AUTOSAR XML (schema 4-0-3)
package /AUTOSAR_NvM/SwComponentTypes
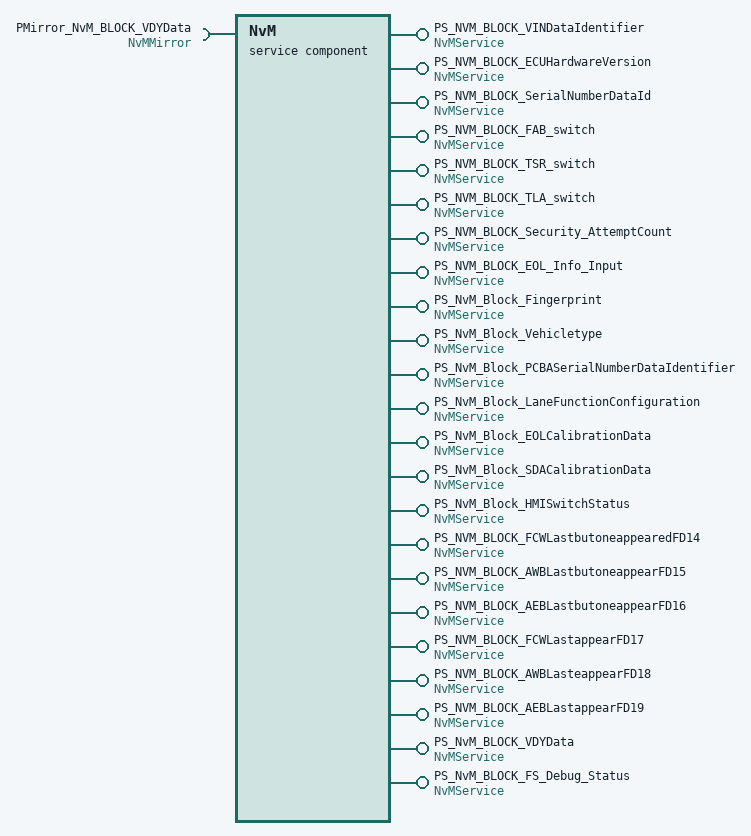
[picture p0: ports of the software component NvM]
  service sw component type NvM
    23 x provide port, all with provided-interface=NvMService:
      PS_NVM_BLOCK_VINDataIdentifier
      PS_NVM_BLOCK_ECUHardwareVersion
      PS_NVM_BLOCK_SerialNumberDataId
      PS_NVM_BLOCK_FAB_switch
      PS_NVM_BLOCK_TSR_switch
      PS_NVM_BLOCK_TLA_switch
      PS_NVM_BLOCK_Security_AttemptCount
      PS_NVM_BLOCK_EOL_Info_Input
      PS_NvM_Block_Fingerprint
      PS_NvM_Block_Vehicletype
      PS_NvM_Block_PCBASerialNumberDataIdentifier
      PS_NvM_Block_LaneFunctionConfiguration
      PS_NvM_Block_EOLCalibrationData
      PS_NvM_Block_SDACalibrationData
      PS_NvM_Block_HMISwitchStatus
      PS_NVM_BLOCK_FCWLastbutoneappearedFD14
      PS_NVM_BLOCK_AWBLastbutoneappearFD15
      PS_NVM_BLOCK_AEBLastbutoneappearFD16
      PS_NVM_BLOCK_FCWLastappearFD17
      PS_NVM_BLOCK_AWBLasteappearFD18
      PS_NVM_BLOCK_AEBLastappearFD19
      PS_NvM_BLOCK_VDYData
      PS_NvM_BLOCK_FS_Debug_Status
    require port PMirror_NvM_BLOCK_VDYData: required-interface=NvMMirror
    behavior NvMIntBeh: handle-termination-and-restart=NO-SUPPORT
      207 x operation invoked event:
        EV_GetErrorStatus_NVM_BLOCK_VINDataIdentifier: start-on-event=RE_GetErrorStatus, operation=PS_NVM_BLOCK_VINDataIdentifier.GetErrorStatus
        EV_SetDataIndex_NVM_BLOCK_VINDataIdentifier: start-on-event=RE_SetDataIndex, operation=PS_NVM_BLOCK_VINDataIdentifier.SetDataIndex
        EV_GetDataIndex_NVM_BLOCK_VINDataIdentifier: start-on-event=RE_GetDataIndex, operation=PS_NVM_BLOCK_VINDataIdentifier.GetDataIndex
        EV_SetRamBlockStatus_NVM_BLOCK_VINDataIdentifier: start-on-event=RE_SetRamBlockStatus, operation=PS_NVM_BLOCK_VINDataIdentifier.SetRamBlockStatus
        EV_ReadBlock_NVM_BLOCK_VINDataIdentifier: start-on-event=RE_ReadBlock, operation=PS_NVM_BLOCK_VINDataIdentifier.ReadBlock
        EV_WriteBlock_NVM_BLOCK_VINDataIdentifier: start-on-event=RE_WriteBlock, operation=PS_NVM_BLOCK_VINDataIdentifier.WriteBlock
        EV_RestoreBlockDefaults_NVM_BLOCK_VINDataIdentifier: start-on-event=RE_RestoreBlockDefaults, operation=PS_NVM_BLOCK_VINDataIdentifier.RestoreBlockDefaults
        EV_EraseBlock_NVM_BLOCK_VINDataIdentifier: start-on-event=RE_EraseBlock, operation=PS_NVM_BLOCK_VINDataIdentifier.EraseBlock
        EV_InvalidateNvBlock_NVM_BLOCK_VINDataIdentifier: start-on-event=RE_InvalidateNvBlock, operation=PS_NVM_BLOCK_VINDataIdentifier.InvalidateNvBlock
        EV_GetErrorStatus_NVM_BLOCK_ECUHardwareVersion: start-on-event=RE_GetErrorStatus, operation=PS_NVM_BLOCK_ECUHardwareVersion.GetErrorStatus
        EV_SetDataIndex_NVM_BLOCK_ECUHardwareVersion: start-on-event=RE_SetDataIndex, operation=PS_NVM_BLOCK_ECUHardwareVersion.SetDataIndex
        EV_GetDataIndex_NVM_BLOCK_ECUHardwareVersion: start-on-event=RE_GetDataIndex, operation=PS_NVM_BLOCK_ECUHardwareVersion.GetDataIndex
        EV_SetRamBlockStatus_NVM_BLOCK_ECUHardwareVersion: start-on-event=RE_SetRamBlockStatus, operation=PS_NVM_BLOCK_ECUHardwareVersion.SetRamBlockStatus
        EV_ReadBlock_NVM_BLOCK_ECUHardwareVersion: start-on-event=RE_ReadBlock, operation=PS_NVM_BLOCK_ECUHardwareVersion.ReadBlock
        EV_WriteBlock_NVM_BLOCK_ECUHardwareVersion: start-on-event=RE_WriteBlock, operation=PS_NVM_BLOCK_ECUHardwareVersion.WriteBlock
        EV_RestoreBlockDefaults_NVM_BLOCK_ECUHardwareVersion: start-on-event=RE_RestoreBlockDefaults, operation=PS_NVM_BLOCK_ECUHardwareVersion.RestoreBlockDefaults
        EV_EraseBlock_NVM_BLOCK_ECUHardwareVersion: start-on-event=RE_EraseBlock, operation=PS_NVM_BLOCK_ECUHardwareVersion.EraseBlock
        EV_InvalidateNvBlock_NVM_BLOCK_ECUHardwareVersion: start-on-event=RE_InvalidateNvBlock, operation=PS_NVM_BLOCK_ECUHardwareVersion.InvalidateNvBlock
        EV_GetErrorStatus_NVM_BLOCK_SerialNumberDataId: start-on-event=RE_GetErrorStatus, operation=PS_NVM_BLOCK_SerialNumberDataId.GetErrorStatus
        EV_SetDataIndex_NVM_BLOCK_SerialNumberDataId: start-on-event=RE_SetDataIndex, operation=PS_NVM_BLOCK_SerialNumberDataId.SetDataIndex
        EV_GetDataIndex_NVM_BLOCK_SerialNumberDataId: start-on-event=RE_GetDataIndex, operation=PS_NVM_BLOCK_SerialNumberDataId.GetDataIndex
        EV_SetRamBlockStatus_NVM_BLOCK_SerialNumberDataId: start-on-event=RE_SetRamBlockStatus, operation=PS_NVM_BLOCK_SerialNumberDataId.SetRamBlockStatus
        EV_ReadBlock_NVM_BLOCK_SerialNumberDataId: start-on-event=RE_ReadBlock, operation=PS_NVM_BLOCK_SerialNumberDataId.ReadBlock
        EV_WriteBlock_NVM_BLOCK_SerialNumberDataId: start-on-event=RE_WriteBlock, operation=PS_NVM_BLOCK_SerialNumberDataId.WriteBlock
        EV_RestoreBlockDefaults_NVM_BLOCK_SerialNumberDataId: start-on-event=RE_RestoreBlockDefaults, operation=PS_NVM_BLOCK_SerialNumberDataId.RestoreBlockDefaults
        EV_EraseBlock_NVM_BLOCK_SerialNumberDataId: start-on-event=RE_EraseBlock, operation=PS_NVM_BLOCK_SerialNumberDataId.EraseBlock
        EV_InvalidateNvBlock_NVM_BLOCK_SerialNumberDataId: start-on-event=RE_InvalidateNvBlock, operation=PS_NVM_BLOCK_SerialNumberDataId.InvalidateNvBlock
        EV_GetErrorStatus_NVM_BLOCK_FAB_switch: start-on-event=RE_GetErrorStatus, operation=PS_NVM_BLOCK_FAB_switch.GetErrorStatus
        EV_SetDataIndex_NVM_BLOCK_FAB_switch: start-on-event=RE_SetDataIndex, operation=PS_NVM_BLOCK_FAB_switch.SetDataIndex
        EV_GetDataIndex_NVM_BLOCK_FAB_switch: start-on-event=RE_GetDataIndex, operation=PS_NVM_BLOCK_FAB_switch.GetDataIndex
        EV_SetRamBlockStatus_NVM_BLOCK_FAB_switch: start-on-event=RE_SetRamBlockStatus, operation=PS_NVM_BLOCK_FAB_switch.SetRamBlockStatus
        EV_ReadBlock_NVM_BLOCK_FAB_switch: start-on-event=RE_ReadBlock, operation=PS_NVM_BLOCK_FAB_switch.ReadBlock
        EV_WriteBlock_NVM_BLOCK_FAB_switch: start-on-event=RE_WriteBlock, operation=PS_NVM_BLOCK_FAB_switch.WriteBlock
        EV_RestoreBlockDefaults_NVM_BLOCK_FAB_switch: start-on-event=RE_RestoreBlockDefaults, operation=PS_NVM_BLOCK_FAB_switch.RestoreBlockDefaults
        EV_EraseBlock_NVM_BLOCK_FAB_switch: start-on-event=RE_EraseBlock, operation=PS_NVM_BLOCK_FAB_switch.EraseBlock
        EV_InvalidateNvBlock_NVM_BLOCK_FAB_switch: start-on-event=RE_InvalidateNvBlock, operation=PS_NVM_BLOCK_FAB_switch.InvalidateNvBlock
        EV_GetErrorStatus_NVM_BLOCK_TSR_switch: start-on-event=RE_GetErrorStatus, operation=PS_NVM_BLOCK_TSR_switch.GetErrorStatus
        EV_SetDataIndex_NVM_BLOCK_TSR_switch: start-on-event=RE_SetDataIndex, operation=PS_NVM_BLOCK_TSR_switch.SetDataIndex
        EV_GetDataIndex_NVM_BLOCK_TSR_switch: start-on-event=RE_GetDataIndex, operation=PS_NVM_BLOCK_TSR_switch.GetDataIndex
        EV_SetRamBlockStatus_NVM_BLOCK_TSR_switch: start-on-event=RE_SetRamBlockStatus, operation=PS_NVM_BLOCK_TSR_switch.SetRamBlockStatus
        EV_ReadBlock_NVM_BLOCK_TSR_switch: start-on-event=RE_ReadBlock, operation=PS_NVM_BLOCK_TSR_switch.ReadBlock
        EV_WriteBlock_NVM_BLOCK_TSR_switch: start-on-event=RE_WriteBlock, operation=PS_NVM_BLOCK_TSR_switch.WriteBlock
        EV_RestoreBlockDefaults_NVM_BLOCK_TSR_switch: start-on-event=RE_RestoreBlockDefaults, operation=PS_NVM_BLOCK_TSR_switch.RestoreBlockDefaults
        EV_EraseBlock_NVM_BLOCK_TSR_switch: start-on-event=RE_EraseBlock, operation=PS_NVM_BLOCK_TSR_switch.EraseBlock
        EV_InvalidateNvBlock_NVM_BLOCK_TSR_switch: start-on-event=RE_InvalidateNvBlock, operation=PS_NVM_BLOCK_TSR_switch.InvalidateNvBlock
        EV_GetErrorStatus_NVM_BLOCK_TLA_switch: start-on-event=RE_GetErrorStatus, operation=PS_NVM_BLOCK_TLA_switch.GetErrorStatus
        EV_SetDataIndex_NVM_BLOCK_TLA_switch: start-on-event=RE_SetDataIndex, operation=PS_NVM_BLOCK_TLA_switch.SetDataIndex
        EV_GetDataIndex_NVM_BLOCK_TLA_switch: start-on-event=RE_GetDataIndex, operation=PS_NVM_BLOCK_TLA_switch.GetDataIndex
        EV_SetRamBlockStatus_NVM_BLOCK_TLA_switch: start-on-event=RE_SetRamBlockStatus, operation=PS_NVM_BLOCK_TLA_switch.SetRamBlockStatus
        EV_ReadBlock_NVM_BLOCK_TLA_switch: start-on-event=RE_ReadBlock, operation=PS_NVM_BLOCK_TLA_switch.ReadBlock
        EV_WriteBlock_NVM_BLOCK_TLA_switch: start-on-event=RE_WriteBlock, operation=PS_NVM_BLOCK_TLA_switch.WriteBlock
        EV_RestoreBlockDefaults_NVM_BLOCK_TLA_switch: start-on-event=RE_RestoreBlockDefaults, operation=PS_NVM_BLOCK_TLA_switch.RestoreBlockDefaults
        EV_EraseBlock_NVM_BLOCK_TLA_switch: start-on-event=RE_EraseBlock, operation=PS_NVM_BLOCK_TLA_switch.EraseBlock
        EV_InvalidateNvBlock_NVM_BLOCK_TLA_switch: start-on-event=RE_InvalidateNvBlock, operation=PS_NVM_BLOCK_TLA_switch.InvalidateNvBlock
        EV_GetErrorStatus_NVM_BLOCK_Security_AttemptCount: start-on-event=RE_GetErrorStatus, operation=PS_NVM_BLOCK_Security_AttemptCount.GetErrorStatus
        EV_SetDataIndex_NVM_BLOCK_Security_AttemptCount: start-on-event=RE_SetDataIndex, operation=PS_NVM_BLOCK_Security_AttemptCount.SetDataIndex
        EV_GetDataIndex_NVM_BLOCK_Security_AttemptCount: start-on-event=RE_GetDataIndex, operation=PS_NVM_BLOCK_Security_AttemptCount.GetDataIndex
        EV_SetRamBlockStatus_NVM_BLOCK_Security_AttemptCount: start-on-event=RE_SetRamBlockStatus, operation=PS_NVM_BLOCK_Security_AttemptCount.SetRamBlockStatus
        EV_ReadBlock_NVM_BLOCK_Security_AttemptCount: start-on-event=RE_ReadBlock, operation=PS_NVM_BLOCK_Security_AttemptCount.ReadBlock
        EV_WriteBlock_NVM_BLOCK_Security_AttemptCount: start-on-event=RE_WriteBlock, operation=PS_NVM_BLOCK_Security_AttemptCount.WriteBlock
        EV_RestoreBlockDefaults_NVM_BLOCK_Security_AttemptCount: start-on-event=RE_RestoreBlockDefaults, operation=PS_NVM_BLOCK_Security_AttemptCount.RestoreBlockDefaults
        EV_EraseBlock_NVM_BLOCK_Security_AttemptCount: start-on-event=RE_EraseBlock, operation=PS_NVM_BLOCK_Security_AttemptCount.EraseBlock
        EV_InvalidateNvBlock_NVM_BLOCK_Security_AttemptCount: start-on-event=RE_InvalidateNvBlock, operation=PS_NVM_BLOCK_Security_AttemptCount.InvalidateNvBlock
        EV_GetErrorStatus_NVM_BLOCK_EOL_Info_Input: start-on-event=RE_GetErrorStatus, operation=PS_NVM_BLOCK_EOL_Info_Input.GetErrorStatus
        EV_SetDataIndex_NVM_BLOCK_EOL_Info_Input: start-on-event=RE_SetDataIndex, operation=PS_NVM_BLOCK_EOL_Info_Input.SetDataIndex
        EV_GetDataIndex_NVM_BLOCK_EOL_Info_Input: start-on-event=RE_GetDataIndex, operation=PS_NVM_BLOCK_EOL_Info_Input.GetDataIndex
        EV_SetRamBlockStatus_NVM_BLOCK_EOL_Info_Input: start-on-event=RE_SetRamBlockStatus, operation=PS_NVM_BLOCK_EOL_Info_Input.SetRamBlockStatus
        EV_ReadBlock_NVM_BLOCK_EOL_Info_Input: start-on-event=RE_ReadBlock, operation=PS_NVM_BLOCK_EOL_Info_Input.ReadBlock
        EV_WriteBlock_NVM_BLOCK_EOL_Info_Input: start-on-event=RE_WriteBlock, operation=PS_NVM_BLOCK_EOL_Info_Input.WriteBlock
        EV_RestoreBlockDefaults_NVM_BLOCK_EOL_Info_Input: start-on-event=RE_RestoreBlockDefaults, operation=PS_NVM_BLOCK_EOL_Info_Input.RestoreBlockDefaults
        EV_EraseBlock_NVM_BLOCK_EOL_Info_Input: start-on-event=RE_EraseBlock, operation=PS_NVM_BLOCK_EOL_Info_Input.EraseBlock
        EV_InvalidateNvBlock_NVM_BLOCK_EOL_Info_Input: start-on-event=RE_InvalidateNvBlock, operation=PS_NVM_BLOCK_EOL_Info_Input.InvalidateNvBlock
        EV_GetErrorStatus_NvM_Block_Fingerprint: start-on-event=RE_GetErrorStatus, operation=PS_NvM_Block_Fingerprint.GetErrorStatus
        EV_SetDataIndex_NvM_Block_Fingerprint: start-on-event=RE_SetDataIndex, operation=PS_NvM_Block_Fingerprint.SetDataIndex
        EV_GetDataIndex_NvM_Block_Fingerprint: start-on-event=RE_GetDataIndex, operation=PS_NvM_Block_Fingerprint.GetDataIndex
        EV_SetRamBlockStatus_NvM_Block_Fingerprint: start-on-event=RE_SetRamBlockStatus, operation=PS_NvM_Block_Fingerprint.SetRamBlockStatus
        EV_ReadBlock_NvM_Block_Fingerprint: start-on-event=RE_ReadBlock, operation=PS_NvM_Block_Fingerprint.ReadBlock
        EV_WriteBlock_NvM_Block_Fingerprint: start-on-event=RE_WriteBlock, operation=PS_NvM_Block_Fingerprint.WriteBlock
        EV_RestoreBlockDefaults_NvM_Block_Fingerprint: start-on-event=RE_RestoreBlockDefaults, operation=PS_NvM_Block_Fingerprint.RestoreBlockDefaults
        EV_EraseBlock_NvM_Block_Fingerprint: start-on-event=RE_EraseBlock, operation=PS_NvM_Block_Fingerprint.EraseBlock
        EV_InvalidateNvBlock_NvM_Block_Fingerprint: start-on-event=RE_InvalidateNvBlock, operation=PS_NvM_Block_Fingerprint.InvalidateNvBlock
        EV_GetErrorStatus_NvM_Block_Vehicletype: start-on-event=RE_GetErrorStatus, operation=PS_NvM_Block_Vehicletype.GetErrorStatus
        EV_SetDataIndex_NvM_Block_Vehicletype: start-on-event=RE_SetDataIndex, operation=PS_NvM_Block_Vehicletype.SetDataIndex
        EV_GetDataIndex_NvM_Block_Vehicletype: start-on-event=RE_GetDataIndex, operation=PS_NvM_Block_Vehicletype.GetDataIndex
        EV_SetRamBlockStatus_NvM_Block_Vehicletype: start-on-event=RE_SetRamBlockStatus, operation=PS_NvM_Block_Vehicletype.SetRamBlockStatus
        EV_ReadBlock_NvM_Block_Vehicletype: start-on-event=RE_ReadBlock, operation=PS_NvM_Block_Vehicletype.ReadBlock
        EV_WriteBlock_NvM_Block_Vehicletype: start-on-event=RE_WriteBlock, operation=PS_NvM_Block_Vehicletype.WriteBlock
        EV_RestoreBlockDefaults_NvM_Block_Vehicletype: start-on-event=RE_RestoreBlockDefaults, operation=PS_NvM_Block_Vehicletype.RestoreBlockDefaults
        EV_EraseBlock_NvM_Block_Vehicletype: start-on-event=RE_EraseBlock, operation=PS_NvM_Block_Vehicletype.EraseBlock
        EV_InvalidateNvBlock_NvM_Block_Vehicletype: start-on-event=RE_InvalidateNvBlock, operation=PS_NvM_Block_Vehicletype.InvalidateNvBlock
        EV_GetErrorStatus_NvM_Block_PCBASerialNumberDataIdentifier: start-on-event=RE_GetErrorStatus, operation=PS_NvM_Block_PCBASerialNumberDataIdentifier.GetErrorStatus
        EV_SetDataIndex_NvM_Block_PCBASerialNumberDataIdentifier: start-on-event=RE_SetDataIndex, operation=PS_NvM_Block_PCBASerialNumberDataIdentifier.SetDataIndex
        EV_GetDataIndex_NvM_Block_PCBASerialNumberDataIdentifier: start-on-event=RE_GetDataIndex, operation=PS_NvM_Block_PCBASerialNumberDataIdentifier.GetDataIndex
        EV_SetRamBlockStatus_NvM_Block_PCBASerialNumberDataIdentifier: start-on-event=RE_SetRamBlockStatus, operation=PS_NvM_Block_PCBASerialNumberDataIdentifier.SetRamBlockStatus
        EV_ReadBlock_NvM_Block_PCBASerialNumberDataIdentifier: start-on-event=RE_ReadBlock, operation=PS_NvM_Block_PCBASerialNumberDataIdentifier.ReadBlock
        EV_WriteBlock_NvM_Block_PCBASerialNumberDataIdentifier: start-on-event=RE_WriteBlock, operation=PS_NvM_Block_PCBASerialNumberDataIdentifier.WriteBlock
        EV_RestoreBlockDefaults_NvM_Block_PCBASerialNumberDataIdentifier: start-on-event=RE_RestoreBlockDefaults, operation=PS_NvM_Block_PCBASerialNumberDataIdentifier.RestoreBlockDefaults
        EV_EraseBlock_NvM_Block_PCBASerialNumberDataIdentifier: start-on-event=RE_EraseBlock, operation=PS_NvM_Block_PCBASerialNumberDataIdentifier.EraseBlock
        EV_InvalidateNvBlock_NvM_Block_PCBASerialNumberDataIdentifier: start-on-event=RE_InvalidateNvBlock, operation=PS_NvM_Block_PCBASerialNumberDataIdentifier.InvalidateNvBlock
        EV_GetErrorStatus_NvM_Block_LaneFunctionConfiguration: start-on-event=RE_GetErrorStatus, operation=PS_NvM_Block_LaneFunctionConfiguration.GetErrorStatus
        EV_SetDataIndex_NvM_Block_LaneFunctionConfiguration: start-on-event=RE_SetDataIndex, operation=PS_NvM_Block_LaneFunctionConfiguration.SetDataIndex
        EV_GetDataIndex_NvM_Block_LaneFunctionConfiguration: start-on-event=RE_GetDataIndex, operation=PS_NvM_Block_LaneFunctionConfiguration.GetDataIndex
        EV_SetRamBlockStatus_NvM_Block_LaneFunctionConfiguration: start-on-event=RE_SetRamBlockStatus, operation=PS_NvM_Block_LaneFunctionConfiguration.SetRamBlockStatus
        EV_ReadBlock_NvM_Block_LaneFunctionConfiguration: start-on-event=RE_ReadBlock, operation=PS_NvM_Block_LaneFunctionConfiguration.ReadBlock
        EV_WriteBlock_NvM_Block_LaneFunctionConfiguration: start-on-event=RE_WriteBlock, operation=PS_NvM_Block_LaneFunctionConfiguration.WriteBlock
        EV_RestoreBlockDefaults_NvM_Block_LaneFunctionConfiguration: start-on-event=RE_RestoreBlockDefaults, operation=PS_NvM_Block_LaneFunctionConfiguration.RestoreBlockDefaults
        EV_EraseBlock_NvM_Block_LaneFunctionConfiguration: start-on-event=RE_EraseBlock, operation=PS_NvM_Block_LaneFunctionConfiguration.EraseBlock
        EV_InvalidateNvBlock_NvM_Block_LaneFunctionConfiguration: start-on-event=RE_InvalidateNvBlock, operation=PS_NvM_Block_LaneFunctionConfiguration.InvalidateNvBlock
        EV_GetErrorStatus_NvM_Block_EOLCalibrationData: start-on-event=RE_GetErrorStatus, operation=PS_NvM_Block_EOLCalibrationData.GetErrorStatus
        EV_SetDataIndex_NvM_Block_EOLCalibrationData: start-on-event=RE_SetDataIndex, operation=PS_NvM_Block_EOLCalibrationData.SetDataIndex
        EV_GetDataIndex_NvM_Block_EOLCalibrationData: start-on-event=RE_GetDataIndex, operation=PS_NvM_Block_EOLCalibrationData.GetDataIndex
        EV_SetRamBlockStatus_NvM_Block_EOLCalibrationData: start-on-event=RE_SetRamBlockStatus, operation=PS_NvM_Block_EOLCalibrationData.SetRamBlockStatus
        EV_ReadBlock_NvM_Block_EOLCalibrationData: start-on-event=RE_ReadBlock, operation=PS_NvM_Block_EOLCalibrationData.ReadBlock
        EV_WriteBlock_NvM_Block_EOLCalibrationData: start-on-event=RE_WriteBlock, operation=PS_NvM_Block_EOLCalibrationData.WriteBlock
        EV_RestoreBlockDefaults_NvM_Block_EOLCalibrationData: start-on-event=RE_RestoreBlockDefaults, operation=PS_NvM_Block_EOLCalibrationData.RestoreBlockDefaults
        EV_EraseBlock_NvM_Block_EOLCalibrationData: start-on-event=RE_EraseBlock, operation=PS_NvM_Block_EOLCalibrationData.EraseBlock
        EV_InvalidateNvBlock_NvM_Block_EOLCalibrationData: start-on-event=RE_InvalidateNvBlock, operation=PS_NvM_Block_EOLCalibrationData.InvalidateNvBlock
        EV_GetErrorStatus_NvM_Block_SDACalibrationData: start-on-event=RE_GetErrorStatus, operation=PS_NvM_Block_SDACalibrationData.GetErrorStatus
        EV_SetDataIndex_NvM_Block_SDACalibrationData: start-on-event=RE_SetDataIndex, operation=PS_NvM_Block_SDACalibrationData.SetDataIndex
        EV_GetDataIndex_NvM_Block_SDACalibrationData: start-on-event=RE_GetDataIndex, operation=PS_NvM_Block_SDACalibrationData.GetDataIndex
        EV_SetRamBlockStatus_NvM_Block_SDACalibrationData: start-on-event=RE_SetRamBlockStatus, operation=PS_NvM_Block_SDACalibrationData.SetRamBlockStatus
        EV_ReadBlock_NvM_Block_SDACalibrationData: start-on-event=RE_ReadBlock, operation=PS_NvM_Block_SDACalibrationData.ReadBlock
        EV_WriteBlock_NvM_Block_SDACalibrationData: start-on-event=RE_WriteBlock, operation=PS_NvM_Block_SDACalibrationData.WriteBlock
        EV_RestoreBlockDefaults_NvM_Block_SDACalibrationData: start-on-event=RE_RestoreBlockDefaults, operation=PS_NvM_Block_SDACalibrationData.RestoreBlockDefaults
        EV_EraseBlock_NvM_Block_SDACalibrationData: start-on-event=RE_EraseBlock, operation=PS_NvM_Block_SDACalibrationData.EraseBlock
        EV_InvalidateNvBlock_NvM_Block_SDACalibrationData: start-on-event=RE_InvalidateNvBlock, operation=PS_NvM_Block_SDACalibrationData.InvalidateNvBlock
        EV_GetErrorStatus_NvM_Block_HMISwitchStatus: start-on-event=RE_GetErrorStatus, operation=PS_NvM_Block_HMISwitchStatus.GetErrorStatus
        EV_SetDataIndex_NvM_Block_HMISwitchStatus: start-on-event=RE_SetDataIndex, operation=PS_NvM_Block_HMISwitchStatus.SetDataIndex
        EV_GetDataIndex_NvM_Block_HMISwitchStatus: start-on-event=RE_GetDataIndex, operation=PS_NvM_Block_HMISwitchStatus.GetDataIndex
        EV_SetRamBlockStatus_NvM_Block_HMISwitchStatus: start-on-event=RE_SetRamBlockStatus, operation=PS_NvM_Block_HMISwitchStatus.SetRamBlockStatus
        EV_ReadBlock_NvM_Block_HMISwitchStatus: start-on-event=RE_ReadBlock, operation=PS_NvM_Block_HMISwitchStatus.ReadBlock
        EV_WriteBlock_NvM_Block_HMISwitchStatus: start-on-event=RE_WriteBlock, operation=PS_NvM_Block_HMISwitchStatus.WriteBlock
        EV_RestoreBlockDefaults_NvM_Block_HMISwitchStatus: start-on-event=RE_RestoreBlockDefaults, operation=PS_NvM_Block_HMISwitchStatus.RestoreBlockDefaults
        EV_EraseBlock_NvM_Block_HMISwitchStatus: start-on-event=RE_EraseBlock, operation=PS_NvM_Block_HMISwitchStatus.EraseBlock
        EV_InvalidateNvBlock_NvM_Block_HMISwitchStatus: start-on-event=RE_InvalidateNvBlock, operation=PS_NvM_Block_HMISwitchStatus.InvalidateNvBlock
        EV_GetErrorStatus_NVM_BLOCK_FCWLastbutoneappearedFD14: start-on-event=RE_GetErrorStatus, operation=PS_NVM_BLOCK_FCWLastbutoneappearedFD14.GetErrorStatus
        EV_SetDataIndex_NVM_BLOCK_FCWLastbutoneappearedFD14: start-on-event=RE_SetDataIndex, operation=PS_NVM_BLOCK_FCWLastbutoneappearedFD14.SetDataIndex
        EV_GetDataIndex_NVM_BLOCK_FCWLastbutoneappearedFD14: start-on-event=RE_GetDataIndex, operation=PS_NVM_BLOCK_FCWLastbutoneappearedFD14.GetDataIndex
        EV_SetRamBlockStatus_NVM_BLOCK_FCWLastbutoneappearedFD14: start-on-event=RE_SetRamBlockStatus, operation=PS_NVM_BLOCK_FCWLastbutoneappearedFD14.SetRamBlockStatus
        EV_ReadBlock_NVM_BLOCK_FCWLastbutoneappearedFD14: start-on-event=RE_ReadBlock, operation=PS_NVM_BLOCK_FCWLastbutoneappearedFD14.ReadBlock
        EV_WriteBlock_NVM_BLOCK_FCWLastbutoneappearedFD14: start-on-event=RE_WriteBlock, operation=PS_NVM_BLOCK_FCWLastbutoneappearedFD14.WriteBlock
        EV_RestoreBlockDefaults_NVM_BLOCK_FCWLastbutoneappearedFD14: start-on-event=RE_RestoreBlockDefaults, operation=PS_NVM_BLOCK_FCWLastbutoneappearedFD14.RestoreBlockDefaults
        EV_EraseBlock_NVM_BLOCK_FCWLastbutoneappearedFD14: start-on-event=RE_EraseBlock, operation=PS_NVM_BLOCK_FCWLastbutoneappearedFD14.EraseBlock
        EV_InvalidateNvBlock_NVM_BLOCK_FCWLastbutoneappearedFD14: start-on-event=RE_InvalidateNvBlock, operation=PS_NVM_BLOCK_FCWLastbutoneappearedFD14.InvalidateNvBlock
        EV_GetErrorStatus_NVM_BLOCK_AWBLastbutoneappearFD15: start-on-event=RE_GetErrorStatus, operation=PS_NVM_BLOCK_AWBLastbutoneappearFD15.GetErrorStatus
        EV_SetDataIndex_NVM_BLOCK_AWBLastbutoneappearFD15: start-on-event=RE_SetDataIndex, operation=PS_NVM_BLOCK_AWBLastbutoneappearFD15.SetDataIndex
        EV_GetDataIndex_NVM_BLOCK_AWBLastbutoneappearFD15: start-on-event=RE_GetDataIndex, operation=PS_NVM_BLOCK_AWBLastbutoneappearFD15.GetDataIndex
        EV_SetRamBlockStatus_NVM_BLOCK_AWBLastbutoneappearFD15: start-on-event=RE_SetRamBlockStatus, operation=PS_NVM_BLOCK_AWBLastbutoneappearFD15.SetRamBlockStatus
        EV_ReadBlock_NVM_BLOCK_AWBLastbutoneappearFD15: start-on-event=RE_ReadBlock, operation=PS_NVM_BLOCK_AWBLastbutoneappearFD15.ReadBlock
        EV_WriteBlock_NVM_BLOCK_AWBLastbutoneappearFD15: start-on-event=RE_WriteBlock, operation=PS_NVM_BLOCK_AWBLastbutoneappearFD15.WriteBlock
        EV_RestoreBlockDefaults_NVM_BLOCK_AWBLastbutoneappearFD15: start-on-event=RE_RestoreBlockDefaults, operation=PS_NVM_BLOCK_AWBLastbutoneappearFD15.RestoreBlockDefaults
        EV_EraseBlock_NVM_BLOCK_AWBLastbutoneappearFD15: start-on-event=RE_EraseBlock, operation=PS_NVM_BLOCK_AWBLastbutoneappearFD15.EraseBlock
        EV_InvalidateNvBlock_NVM_BLOCK_AWBLastbutoneappearFD15: start-on-event=RE_InvalidateNvBlock, operation=PS_NVM_BLOCK_AWBLastbutoneappearFD15.InvalidateNvBlock
        EV_GetErrorStatus_NVM_BLOCK_AEBLastbutoneappearFD16: start-on-event=RE_GetErrorStatus, operation=PS_NVM_BLOCK_AEBLastbutoneappearFD16.GetErrorStatus
        EV_SetDataIndex_NVM_BLOCK_AEBLastbutoneappearFD16: start-on-event=RE_SetDataIndex, operation=PS_NVM_BLOCK_AEBLastbutoneappearFD16.SetDataIndex
        EV_GetDataIndex_NVM_BLOCK_AEBLastbutoneappearFD16: start-on-event=RE_GetDataIndex, operation=PS_NVM_BLOCK_AEBLastbutoneappearFD16.GetDataIndex
        EV_SetRamBlockStatus_NVM_BLOCK_AEBLastbutoneappearFD16: start-on-event=RE_SetRamBlockStatus, operation=PS_NVM_BLOCK_AEBLastbutoneappearFD16.SetRamBlockStatus
        EV_ReadBlock_NVM_BLOCK_AEBLastbutoneappearFD16: start-on-event=RE_ReadBlock, operation=PS_NVM_BLOCK_AEBLastbutoneappearFD16.ReadBlock
        EV_WriteBlock_NVM_BLOCK_AEBLastbutoneappearFD16: start-on-event=RE_WriteBlock, operation=PS_NVM_BLOCK_AEBLastbutoneappearFD16.WriteBlock
        EV_RestoreBlockDefaults_NVM_BLOCK_AEBLastbutoneappearFD16: start-on-event=RE_RestoreBlockDefaults, operation=PS_NVM_BLOCK_AEBLastbutoneappearFD16.RestoreBlockDefaults
        EV_EraseBlock_NVM_BLOCK_AEBLastbutoneappearFD16: start-on-event=RE_EraseBlock, operation=PS_NVM_BLOCK_AEBLastbutoneappearFD16.EraseBlock
        EV_InvalidateNvBlock_NVM_BLOCK_AEBLastbutoneappearFD16: start-on-event=RE_InvalidateNvBlock, operation=PS_NVM_BLOCK_AEBLastbutoneappearFD16.InvalidateNvBlock
        EV_GetErrorStatus_NVM_BLOCK_FCWLastappearFD17: start-on-event=RE_GetErrorStatus, operation=PS_NVM_BLOCK_FCWLastappearFD17.GetErrorStatus
        EV_SetDataIndex_NVM_BLOCK_FCWLastappearFD17: start-on-event=RE_SetDataIndex, operation=PS_NVM_BLOCK_FCWLastappearFD17.SetDataIndex
        EV_GetDataIndex_NVM_BLOCK_FCWLastappearFD17: start-on-event=RE_GetDataIndex, operation=PS_NVM_BLOCK_FCWLastappearFD17.GetDataIndex
        EV_SetRamBlockStatus_NVM_BLOCK_FCWLastappearFD17: start-on-event=RE_SetRamBlockStatus, operation=PS_NVM_BLOCK_FCWLastappearFD17.SetRamBlockStatus
        EV_ReadBlock_NVM_BLOCK_FCWLastappearFD17: start-on-event=RE_ReadBlock, operation=PS_NVM_BLOCK_FCWLastappearFD17.ReadBlock
        EV_WriteBlock_NVM_BLOCK_FCWLastappearFD17: start-on-event=RE_WriteBlock, operation=PS_NVM_BLOCK_FCWLastappearFD17.WriteBlock
        EV_RestoreBlockDefaults_NVM_BLOCK_FCWLastappearFD17: start-on-event=RE_RestoreBlockDefaults, operation=PS_NVM_BLOCK_FCWLastappearFD17.RestoreBlockDefaults
        EV_EraseBlock_NVM_BLOCK_FCWLastappearFD17: start-on-event=RE_EraseBlock, operation=PS_NVM_BLOCK_FCWLastappearFD17.EraseBlock
        EV_InvalidateNvBlock_NVM_BLOCK_FCWLastappearFD17: start-on-event=RE_InvalidateNvBlock, operation=PS_NVM_BLOCK_FCWLastappearFD17.InvalidateNvBlock
        EV_GetErrorStatus_NVM_BLOCK_AWBLasteappearFD18: start-on-event=RE_GetErrorStatus, operation=PS_NVM_BLOCK_AWBLasteappearFD18.GetErrorStatus
        EV_SetDataIndex_NVM_BLOCK_AWBLasteappearFD18: start-on-event=RE_SetDataIndex, operation=PS_NVM_BLOCK_AWBLasteappearFD18.SetDataIndex
        EV_GetDataIndex_NVM_BLOCK_AWBLasteappearFD18: start-on-event=RE_GetDataIndex, operation=PS_NVM_BLOCK_AWBLasteappearFD18.GetDataIndex
        EV_SetRamBlockStatus_NVM_BLOCK_AWBLasteappearFD18: start-on-event=RE_SetRamBlockStatus, operation=PS_NVM_BLOCK_AWBLasteappearFD18.SetRamBlockStatus
        EV_ReadBlock_NVM_BLOCK_AWBLasteappearFD18: start-on-event=RE_ReadBlock, operation=PS_NVM_BLOCK_AWBLasteappearFD18.ReadBlock
        EV_WriteBlock_NVM_BLOCK_AWBLasteappearFD18: start-on-event=RE_WriteBlock, operation=PS_NVM_BLOCK_AWBLasteappearFD18.WriteBlock
        EV_RestoreBlockDefaults_NVM_BLOCK_AWBLasteappearFD18: start-on-event=RE_RestoreBlockDefaults, operation=PS_NVM_BLOCK_AWBLasteappearFD18.RestoreBlockDefaults
        EV_EraseBlock_NVM_BLOCK_AWBLasteappearFD18: start-on-event=RE_EraseBlock, operation=PS_NVM_BLOCK_AWBLasteappearFD18.EraseBlock
        EV_InvalidateNvBlock_NVM_BLOCK_AWBLasteappearFD18: start-on-event=RE_InvalidateNvBlock, operation=PS_NVM_BLOCK_AWBLasteappearFD18.InvalidateNvBlock
        EV_GetErrorStatus_NVM_BLOCK_AEBLastappearFD19: start-on-event=RE_GetErrorStatus, operation=PS_NVM_BLOCK_AEBLastappearFD19.GetErrorStatus
        EV_SetDataIndex_NVM_BLOCK_AEBLastappearFD19: start-on-event=RE_SetDataIndex, operation=PS_NVM_BLOCK_AEBLastappearFD19.SetDataIndex
        EV_GetDataIndex_NVM_BLOCK_AEBLastappearFD19: start-on-event=RE_GetDataIndex, operation=PS_NVM_BLOCK_AEBLastappearFD19.GetDataIndex
        EV_SetRamBlockStatus_NVM_BLOCK_AEBLastappearFD19: start-on-event=RE_SetRamBlockStatus, operation=PS_NVM_BLOCK_AEBLastappearFD19.SetRamBlockStatus
        EV_ReadBlock_NVM_BLOCK_AEBLastappearFD19: start-on-event=RE_ReadBlock, operation=PS_NVM_BLOCK_AEBLastappearFD19.ReadBlock
        EV_WriteBlock_NVM_BLOCK_AEBLastappearFD19: start-on-event=RE_WriteBlock, operation=PS_NVM_BLOCK_AEBLastappearFD19.WriteBlock
        EV_RestoreBlockDefaults_NVM_BLOCK_AEBLastappearFD19: start-on-event=RE_RestoreBlockDefaults, operation=PS_NVM_BLOCK_AEBLastappearFD19.RestoreBlockDefaults
        EV_EraseBlock_NVM_BLOCK_AEBLastappearFD19: start-on-event=RE_EraseBlock, operation=PS_NVM_BLOCK_AEBLastappearFD19.EraseBlock
        EV_InvalidateNvBlock_NVM_BLOCK_AEBLastappearFD19: start-on-event=RE_InvalidateNvBlock, operation=PS_NVM_BLOCK_AEBLastappearFD19.InvalidateNvBlock
        EV_GetErrorStatus_NvM_BLOCK_VDYData: start-on-event=RE_GetErrorStatus, operation=PS_NvM_BLOCK_VDYData.GetErrorStatus
        EV_SetDataIndex_NvM_BLOCK_VDYData: start-on-event=RE_SetDataIndex, operation=PS_NvM_BLOCK_VDYData.SetDataIndex
        EV_GetDataIndex_NvM_BLOCK_VDYData: start-on-event=RE_GetDataIndex, operation=PS_NvM_BLOCK_VDYData.GetDataIndex
        EV_SetRamBlockStatus_NvM_BLOCK_VDYData: start-on-event=RE_SetRamBlockStatus, operation=PS_NvM_BLOCK_VDYData.SetRamBlockStatus
        EV_ReadBlock_NvM_BLOCK_VDYData: start-on-event=RE_ReadBlock, operation=PS_NvM_BLOCK_VDYData.ReadBlock
        EV_WriteBlock_NvM_BLOCK_VDYData: start-on-event=RE_WriteBlock, operation=PS_NvM_BLOCK_VDYData.WriteBlock
        EV_RestoreBlockDefaults_NvM_BLOCK_VDYData: start-on-event=RE_RestoreBlockDefaults, operation=PS_NvM_BLOCK_VDYData.RestoreBlockDefaults
        EV_EraseBlock_NvM_BLOCK_VDYData: start-on-event=RE_EraseBlock, operation=PS_NvM_BLOCK_VDYData.EraseBlock
        EV_InvalidateNvBlock_NvM_BLOCK_VDYData: start-on-event=RE_InvalidateNvBlock, operation=PS_NvM_BLOCK_VDYData.InvalidateNvBlock
        EV_GetErrorStatus_NvM_BLOCK_FS_Debug_Status: start-on-event=RE_GetErrorStatus, operation=PS_NvM_BLOCK_FS_Debug_Status.GetErrorStatus
        EV_SetDataIndex_NvM_BLOCK_FS_Debug_Status: start-on-event=RE_SetDataIndex, operation=PS_NvM_BLOCK_FS_Debug_Status.SetDataIndex
        EV_GetDataIndex_NvM_BLOCK_FS_Debug_Status: start-on-event=RE_GetDataIndex, operation=PS_NvM_BLOCK_FS_Debug_Status.GetDataIndex
        EV_SetRamBlockStatus_NvM_BLOCK_FS_Debug_Status: start-on-event=RE_SetRamBlockStatus, operation=PS_NvM_BLOCK_FS_Debug_Status.SetRamBlockStatus
        EV_ReadBlock_NvM_BLOCK_FS_Debug_Status: start-on-event=RE_ReadBlock, operation=PS_NvM_BLOCK_FS_Debug_Status.ReadBlock
        EV_WriteBlock_NvM_BLOCK_FS_Debug_Status: start-on-event=RE_WriteBlock, operation=PS_NvM_BLOCK_FS_Debug_Status.WriteBlock
        EV_RestoreBlockDefaults_NvM_BLOCK_FS_Debug_Status: start-on-event=RE_RestoreBlockDefaults, operation=PS_NvM_BLOCK_FS_Debug_Status.RestoreBlockDefaults
        EV_EraseBlock_NvM_BLOCK_FS_Debug_Status: start-on-event=RE_EraseBlock, operation=PS_NvM_BLOCK_FS_Debug_Status.EraseBlock
        EV_InvalidateNvBlock_NvM_BLOCK_FS_Debug_Status: start-on-event=RE_InvalidateNvBlock, operation=PS_NvM_BLOCK_FS_Debug_Status.InvalidateNvBlock
      port-api-options:
        {enable-take-address=true, indirect-api=false, port-defined-argument-value{value=4, value-type=NvM_BlockIdType}, port=PS_NVM_BLOCK_VINDataIdentifier}
        {enable-take-address=true, indirect-api=false, port-defined-argument-value{value=5, value-type=NvM_BlockIdType}, port=PS_NVM_BLOCK_ECUHardwareVersion}
        {enable-take-address=true, indirect-api=false, port-defined-argument-value{value=6, value-type=NvM_BlockIdType}, port=PS_NVM_BLOCK_SerialNumberDataId}
        {enable-take-address=true, indirect-api=false, port-defined-argument-value{value=7, value-type=NvM_BlockIdType}, port=PS_NVM_BLOCK_FAB_switch}
        {enable-take-address=true, indirect-api=false, port-defined-argument-value{value=8, value-type=NvM_BlockIdType}, port=PS_NVM_BLOCK_TSR_switch}
        {enable-take-address=true, indirect-api=false, port-defined-argument-value{value=9, value-type=NvM_BlockIdType}, port=PS_NVM_BLOCK_TLA_switch}
        {enable-take-address=true, indirect-api=false, port-defined-argument-value{value=10, value-type=NvM_BlockIdType}, port=PS_NVM_BLOCK_Security_AttemptCount}
        {enable-take-address=true, indirect-api=false, port-defined-argument-value{value=11, value-type=NvM_BlockIdType}, port=PS_NVM_BLOCK_EOL_Info_Input}
        {enable-take-address=true, indirect-api=false, port-defined-argument-value{value=16, value-type=NvM_BlockIdType}, port=PS_NvM_Block_Fingerprint}
        {enable-take-address=true, indirect-api=false, port-defined-argument-value{value=17, value-type=NvM_BlockIdType}, port=PS_NvM_Block_Vehicletype}
        {enable-take-address=true, indirect-api=false, port-defined-argument-value{value=18, value-type=NvM_BlockIdType}, port=PS_NvM_Block_PCBASerialNumberDataIdentifier}
        {enable-take-address=true, indirect-api=false, port-defined-argument-value{value=19, value-type=NvM_BlockIdType}, port=PS_NvM_Block_LaneFunctionConfiguration}
        {enable-take-address=true, indirect-api=false, port-defined-argument-value{value=20, value-type=NvM_BlockIdType}, port=PS_NvM_Block_EOLCalibrationData}
        {enable-take-address=true, indirect-api=false, port-defined-argument-value{value=21, value-type=NvM_BlockIdType}, port=PS_NvM_Block_SDACalibrationData}
        {enable-take-address=true, indirect-api=false, port-defined-argument-value{value=23, value-type=NvM_BlockIdType}, port=PS_NvM_Block_HMISwitchStatus}
        {enable-take-address=true, indirect-api=false, port-defined-argument-value{value=24, value-type=NvM_BlockIdType}, port=PS_NVM_BLOCK_FCWLastbutoneappearedFD14}
        {enable-take-address=true, indirect-api=false, port-defined-argument-value{value=25, value-type=NvM_BlockIdType}, port=PS_NVM_BLOCK_AWBLastbutoneappearFD15}
        {enable-take-address=true, indirect-api=false, port-defined-argument-value{value=26, value-type=NvM_BlockIdType}, port=PS_NVM_BLOCK_AEBLastbutoneappearFD16}
        {enable-take-address=true, indirect-api=false, port-defined-argument-value{value=27, value-type=NvM_BlockIdType}, port=PS_NVM_BLOCK_FCWLastappearFD17}
        {enable-take-address=true, indirect-api=false, port-defined-argument-value{value=28, value-type=NvM_BlockIdType}, port=PS_NVM_BLOCK_AWBLasteappearFD18}
        {enable-take-address=true, indirect-api=false, port-defined-argument-value{value=29, value-type=NvM_BlockIdType}, port=PS_NVM_BLOCK_AEBLastappearFD19}
        {enable-take-address=true, indirect-api=false, port-defined-argument-value{value=30, value-type=NvM_BlockIdType}, port=PS_NvM_BLOCK_VDYData}
        {enable-take-address=true, indirect-api=false, port-defined-argument-value{value=31, value-type=NvM_BlockIdType}, port=PS_NvM_BLOCK_FS_Debug_Status}
        enable-take-address=true, indirect-api=false, port=PMirror_NvM_BLOCK_VDYData
      10 x runnable, all with can-be-invoked-concurrently=true:
        RE_MainFunction: symbol=NvM_MainFunction
          sync call sscp_ReadRamBlockFromNvm_NvM_BLOCK_VDYData: operation=PMirror_NvM_BLOCK_VDYData.ReadRamBlockFromNvm, timeout=0.0
          sync call sscp_WriteRamBlockToNvm_NvM_BLOCK_VDYData: operation=PMirror_NvM_BLOCK_VDYData.WriteRamBlockToNvm, timeout=0.0
        RE_GetErrorStatus: arguments=[symbol=BlockId, symbol=RequestResultPtr], symbol=NvM_Rte_GetErrorStatus
        RE_SetDataIndex: arguments=[symbol=BlockId, symbol=DataIndex], symbol=NvM_Rte_SetDataIndex
        RE_GetDataIndex: arguments=[symbol=BlockId, symbol=DataIndex], symbol=NvM_Rte_GetDataIndex
        RE_SetRamBlockStatus: arguments=[symbol=BlockId, symbol=BlockChanged], symbol=NvM_Rte_SetRamBlockStatus
        RE_ReadBlock: arguments=[symbol=BlockId, symbol=NvM_DstPtr], symbol=NvM_Rte_ReadBlock
        RE_WriteBlock: arguments=[symbol=BlockId, symbol=NvM_SrcPtr], symbol=NvM_Rte_WriteBlock
        RE_RestoreBlockDefaults: arguments=[symbol=BlockId, symbol=NvM_DestPtr], symbol=NvM_Rte_RestoreBlockDefaults
        RE_EraseBlock: runnable-entity-argument=symbol=BlockId, symbol=NvM_Rte_EraseNvBlock
        RE_InvalidateNvBlock: runnable-entity-argument=symbol=BlockId, symbol=NvM_Rte_InvalidateNvBlock
package /EB_NvM/SwcImplementations
  swc implementation NvMImpl: programming-language=C, sw-version=1.0.0, vendor-id=1, behavior=NvMIntBeh
    code-descriptors:
      code Code: artifact-descriptors=autosar-engineering-object={short-label=EngObject, category=SWSRC}
    resource consumption Resources
      memory section CODE: sw-addrmethod=CODE
